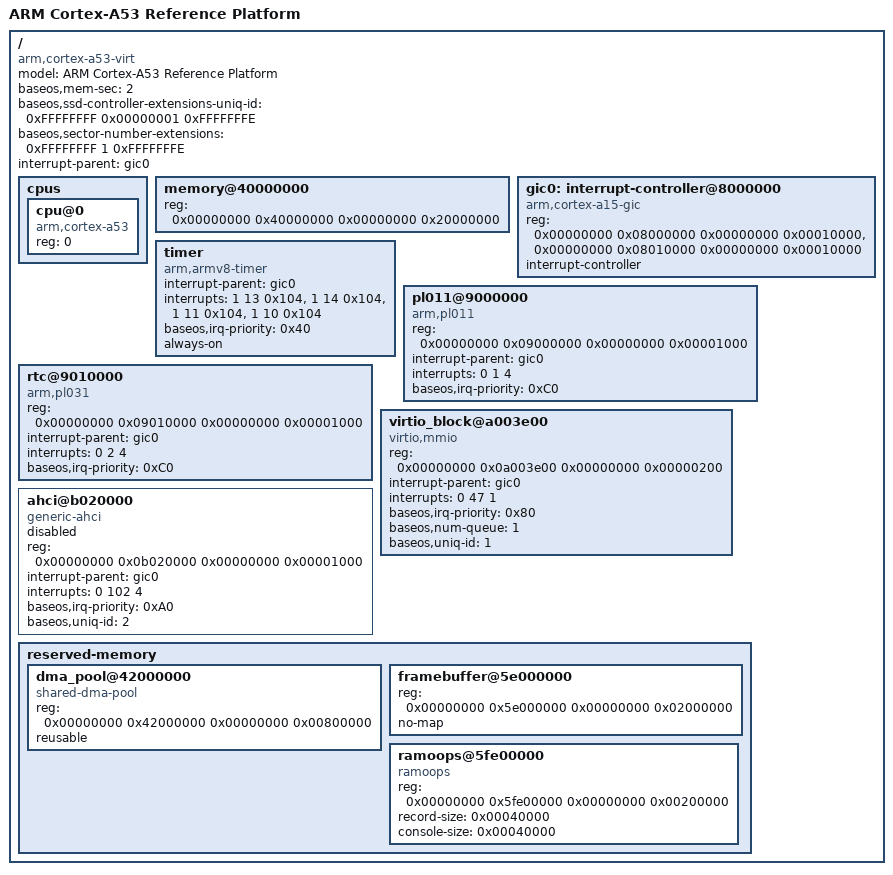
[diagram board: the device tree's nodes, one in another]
/dts-v1/;

/memreserve/ 0x0000000040000000 0x0000000000100000;
/memreserve/ 0x0000000040100000 0x0000000000100000;
/memreserve/ 0x0000000040200000 0x0000000001000000;

/ {
    #address-cells = <2>;
    #size-cells = <2>;
    model = "ARM Cortex-A53 Reference Platform";
    compatible = "arm,cortex-a53-virt", "arm,vexpress";

    baseos,mem-sec = <2>  ; /* 0=none , 1 = MPU , 2=MMU */ 

/*
  This property stores the ssd controller whose storgae device stores the extensions meta Data ! 
  The value 1 here is the uniq-id value of the ssd controller 
  the value -1(0xFFFFFFFF) here is the delimiter which tells the end of some uniq-id and starting of some new uniq-id 
  and the value -2(0xFFFFFFFE) represents the end of the block ! 
*/
    baseos,ssd-controller-extensions-uniq-id = < 0xFFFFFFFF 0x00000001 0xFFFFFFFE > ;

    /*
    Stores the sector numbers in sequential order where the metadata of the extensions is placed , the sectors will be read in strict sequential order so it is the user work to give proper dtb 
      the value -1 here is the delimiter which tells the end!
  and the value -2 represents the end of the block ! 
    */

    baseos,sector-number-extensions = < 0xFFFFFFFF 1 0xFFFFFFFE> ;

    interrupt-parent = <&gic0>;

    cpus {
        #address-cells = <1>;
        #size-cells = <0>;
        cpu@0 {
            device_type = "cpu";
            compatible = "arm,cortex-a53";
            reg = <0>;
        };
    };

    memory@40000000 {
        device_type = "memory";
        reg = <0x00000000 0x40000000 0x00000000 0x20000000>;
    };

    gic0: interrupt-controller@8000000 {
        compatible = "arm,cortex-a15-gic";
        reg = <0x00000000 0x08000000 0x00000000 0x00010000>,
              <0x00000000 0x08010000 0x00000000 0x00010000>;
        interrupt-controller;
        #interrupt-cells = <3>;
    };

    timer {
        compatible = "arm,armv8-timer";
        interrupt-parent = <&gic0>;
        interrupts = <1 13 0x104>,
                     <1 14 0x104>,
                     <1 11 0x104>,
                     <1 10 0x104>;
        baseos,irq-priority = <0x40>;
        always-on;
    };

    pl011@9000000 {
        compatible = "arm,pl011", "arm,primecell";
        reg = <0x00000000 0x09000000 0x00000000 0x00001000>;
        interrupt-parent = <&gic0>;
        interrupts = <0 1 4>;
        baseos,irq-priority = <0xC0>;
    };

    rtc@9010000 {
        compatible = "arm,pl031", "arm,primecell";
        reg = <0x00000000 0x09010000 0x00000000 0x00001000>;
        interrupt-parent = <&gic0>;
        interrupts = <0 2 4>;
        baseos,irq-priority = <0xC0>;
    };

    virtio_block@a003e00 {
        compatible = "virtio,mmio";
        reg = <0x00000000 0x0a003e00 0x00000000 0x00000200>;
        interrupt-parent = <&gic0>;
        interrupts = <0 47 1>;
        baseos,irq-priority = <0x80>;
        baseos,num-queue = <1> ; 
        baseos,uniq-id = <1> ; 
    };

    ahci@b020000 {
        compatible = "generic-ahci";
        reg = <0x00000000 0x0b020000 0x00000000 0x00001000>;
        interrupt-parent = <&gic0>;
        interrupts = <0 102 4>;
        status = "disabled" ; 
        baseos,irq-priority = <0xA0>;
        baseos,uniq-id = <2> ; 
    };

    reserved-memory {
        #address-cells = <2>;
        #size-cells = <2>;
        ranges;

        dma_pool@42000000 {
            compatible = "shared-dma-pool";
            reg = <0x00000000 0x42000000 0x00000000 0x00800000>;
            reusable;
        };

        framebuffer@5e000000 {
            reg = <0x00000000 0x5e000000 0x00000000 0x02000000>;
            no-map;
        };

        ramoops@5fe00000 {
            compatible = "ramoops";
            reg = <0x00000000 0x5fe00000 0x00000000 0x00200000>;
            record-size = <0x00040000>;
            console-size = <0x00040000>;
        };
    };
};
